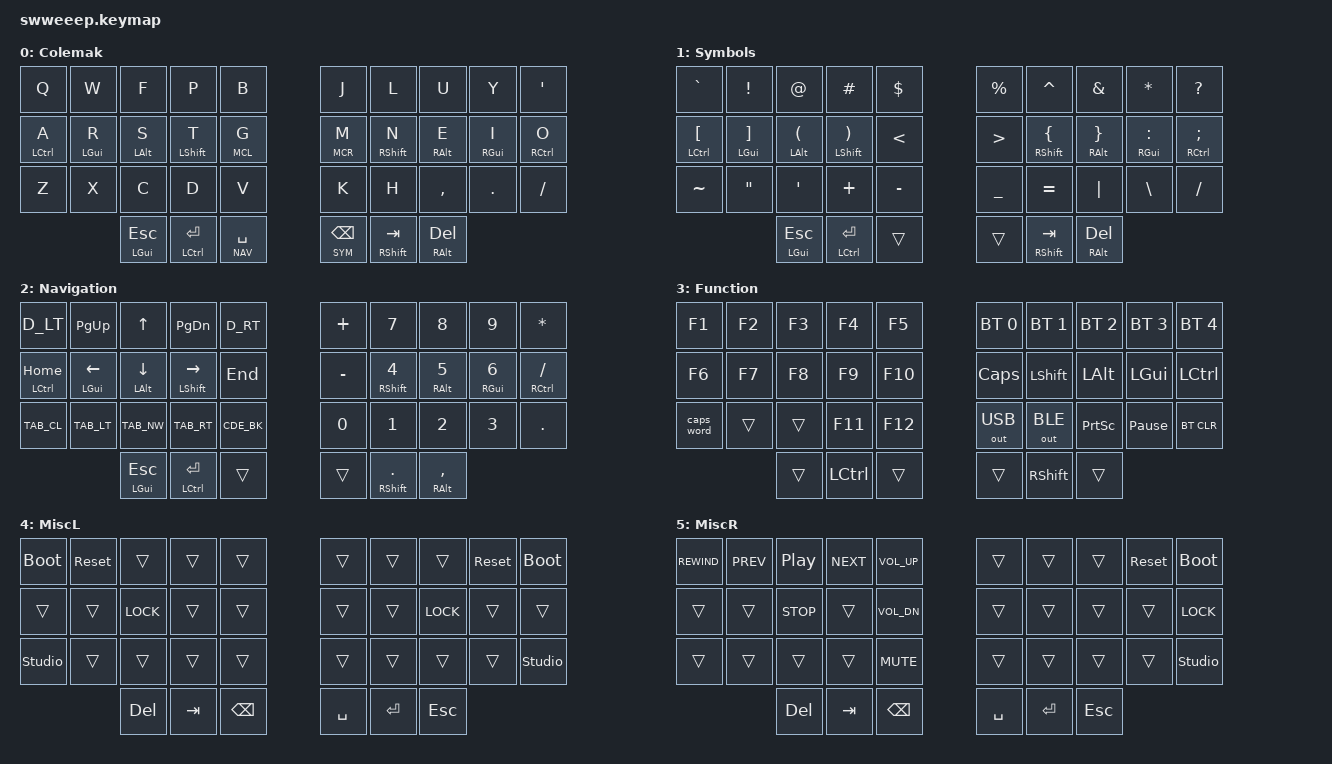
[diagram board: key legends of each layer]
#include <behaviors.dtsi>
#include <dt-bindings/zmk/keys.h>
#include <dt-bindings/zmk/bt.h>
#include <dt-bindings/zmk/outputs.h>

// Layer aliases
#define CMK  0
#define SYM  1
#define NAV  2
#define FUN  3
#define MCL  4
#define MCR  5

// Desktop keycodes
#define D_LT   LC(LA(LEFT))
#define D_RT   LC(LA(RIGHT))

// Browser keycodes
#define TAB_NW LC(T)
#define TAB_RT LC(TAB)
#define TAB_LT LC(LS(TAB))
#define TAB_CL LC(W)

// VS Code keycodes
#define CDE_BK LC(LA(MINUS))
#define CDE_FD LC(LS(MINUS))

// Key position groups
#define KEYS_L 0 1 2 3 4 10 11 12 13 14 20 21 22 23 24
#define KEYS_R 5 6 7 8 9 15 16 17 18 19 25 26 27 28 29
#define THUMBS 30 31 32 33 34 35 

// #include "combos.dtsi"

&caps_word {
    continue-list = <UNDERSCORE MINUS BSPC DEL N1 N2 N3 N4 N5 N6 N7 N8 N9 N0>;
};


/ {
    behaviors {    
          hml: homerow_mods_left {
               compatible = "zmk,behavior-hold-tap";
               display-name = "HM Left";
               #binding-cells = <2>;
               flavor = "balanced";
               require-prior-idle-ms = <150>;
               tapping-term-ms = <200>;
               quick-tap-ms = <150>;
               bindings = <&kp>, <&kp>;
               hold-trigger-key-positions = <KEYS_R THUMBS>;
               hold-trigger-on-release;
          };
          hmr: homerow_mods_right {
               compatible = "zmk,behavior-hold-tap";
               display-name = "HM Right";
               #binding-cells = <2>;
               flavor = "balanced";
               require-prior-idle-ms = <150>;
               tapping-term-ms = <200>;
               quick-tap-ms = <150>;
               bindings = <&kp>, <&kp>;
               hold-trigger-key-positions = <KEYS_L THUMBS>;
               hold-trigger-on-release;
          };
          hmt: homerow_mods_toggle {
               compatible = "zmk,behavior-hold-tap";
               display-name = "HM Toggle";
               #binding-cells = <2>;
               flavor = "balanced";
               require-prior-idle-ms = <150>;
               tapping-term-ms = <200>;
               quick-tap-ms = <150>;
               bindings = <&mo>, <&kp>;
               hold-trigger-key-positions = <KEYS_L KEYS_R THUMBS>;
               hold-trigger-on-release;
          };
          ltr: layer_toggle_right {
               compatible = "zmk,behavior-hold-tap";
               display-name = "LT Right";
               #binding-cells = <2>;
               flavor = "hold-preferred";
               tapping-term-ms = <200>;
               bindings = <&mo>, <&kp>;
          };
          ltl: layer_toggle_left {
               compatible = "zmk,behavior-hold-tap";
               display-name = "LT Left";
               #binding-cells = <2>;
               flavor = "hold-preferred";
               tapping-term-ms = <200>;
               bindings = <&mo>, <&kp>;
          };
    };

    cond_layers {
        compatible = "zmk,conditional-layers";
        // Define FUN layer as tri-state
        func_tristate {
            if-layers = <NAV SYM>;
            then-layer = <FUN>;
        };
    };

    keymap {
       compatible = "zmk,keymap";
       Colemak_layer {
          display-name = "Colemak";
          bindings = <

// ╭─────────────┬─────────────┬─────────────┬─────────────┬─────────────╮   ╭─────────────┬─────────────┬─────────────┬─────────────┬─────────────╮
     &kp Q         &kp W         &kp F         &kp P         &kp B             &kp J         &kp L         &kp U         &kp Y         &kp SQT
// ├─────────────┼─────────────┼─────────────┼─────────────┼─────────────┤   ├─────────────┼─────────────┼─────────────┼─────────────┼─────────────┤
     &hml LCTRL A  &hml LGUI R   &hml LALT S   &hml LSHFT T  &hmt MCL G        &hmt MCR M    &hmr RSHFT N  &hmr RALT E   &hmr RGUI I   &hmr RCTRL O
// ├─────────────┼─────────────┼─────────────┼─────────────┼─────────────┤   ├─────────────┼─────────────┼─────────────┼─────────────┼─────────────┤
     &kp Z         &kp X         &kp C         &kp D         &kp V             &kp K         &kp H         &kp COMMA     &kp DOT       &kp SLASH
// ╰─────────────┴─────────────┴─────────────┼─────────────┼─────────────┤   ├─────────────┼─────────────┼─────────────┴─────────────┴─────────────╯
                                 &mt LGUI ESC  &mt LCTRL RET &ltr NAV SPACE    &ltl SYM BSPC &mt RSHFT TAB &mt RALT DEL
//                             ╰─────────────┴─────────────┴─────────────╯   ╰─────────────┴─────────────┴─────────────╯
        >;

     };
     Symbols_layer {
          display-name = "Symbols";
          bindings = <

// ╭─────────────┬─────────────┬─────────────┬─────────────┬─────────────╮   ╭─────────────┬─────────────┬─────────────┬─────────────┬─────────────╮
     &kp GRAVE     &kp EXCL      &kp AT        &kp HASH      &kp DLLR          &kp PRCNT     &kp CARET     &kp AMPS      &kp ASTRK     &kp QMARK
// ├─────────────┼─────────────┼─────────────┼─────────────┼─────────────┤   ├─────────────┼─────────────┼─────────────┼─────────────┼─────────────┤
     &hml LCTRL LBKT  &hml LGUI RBKT &hml LALT LPAR &hml LSHIFT RPAR &kp LT    &kp GT   &hmr RSHFT LBRC &hmr RALT RBRC &hmr RGUI COLON &hmr RCTRL SEMI
// ├─────────────┼─────────────┼─────────────┼─────────────┼─────────────┤   ├─────────────┼─────────────┼─────────────┼─────────────┼─────────────┤
     &kp TILDE     &kp DQT       &kp SQT       &kp PLUS      &kp MINUS         &kp UNDER      &kp EQUAL     &kp PIPE     &kp BSLH       &kp SLASH
// ╰─────────────┴─────────────┴─────────────┼─────────────┼─────────────┤   ├─────────────┼─────────────┼─────────────┴─────────────┴─────────────╯
                                 &mt LGUI ESC  &mt LCTRL RET &trans            &trans        &mt RSHFT TAB &mt RALT DEL
//                             ╰─────────────┴─────────────┴─────────────╯   ╰─────────────┴─────────────┴─────────────╯
        >;

     };
     Navigation_layer {
          display-name = "Navigation";
          bindings = <

// ╭─────────────┬─────────────┬─────────────┬─────────────┬─────────────╮   ╭─────────────┬─────────────┬─────────────┬─────────────┬─────────────╮
     &kp D_LT      &kp PG_UP     &kp UP        &kp PG_DN     &kp D_RT           &kp PLUS      &kp N7        &kp N8       &kp N9         &kp STAR
// ├─────────────┼─────────────┼─────────────┼─────────────┼─────────────┤   ├─────────────┼─────────────┼─────────────┼─────────────┼─────────────┤
     &hml LCTRL HOME &hml LGUI LEFT &hml LALT DOWN &hml LSHFT RIGHT &kp END     &kp MINUS     &hmr RSHFT N4 &hmr RALT N5 &hmr RGUI N6   &hmr RCTRL SLASH
// ├─────────────┼─────────────┼─────────────┼─────────────┼─────────────┤   ├─────────────┼─────────────┼─────────────┼─────────────┼─────────────┤
     &kp TAB_CL    &kp TAB_LT    &kp TAB_NW    &kp TAB_RT    &kp CDE_BK         &kp N0        &kp N1        &kp N2        &kp N3         &kp DOT
// ╰─────────────┴─────────────┴─────────────┼─────────────┼─────────────┤   ├─────────────┼─────────────┼─────────────┴─────────────┴─────────────╯
                                 &mt LGUI ESC  &mt LCTRL RET &trans             &trans        &mt RSHFT DOT &mt RALT COMMA
//                             ╰─────────────┴─────────────┴─────────────╯   ╰─────────────┴─────────────┴─────────────╯
        >;


     };
     Function_layer {
          display-name = "Function";
          bindings = <

// ╭─────────────┬─────────────┬─────────────┬─────────────┬─────────────╮   ╭─────────────┬─────────────┬─────────────┬─────────────┬─────────────╮
     &kp F1        &kp F2        &kp F3        &kp F4        &kp F5            &bt BT_SEL 0  &bt BT_SEL 1  &bt BT_SEL 2  &bt BT_SEL 3  &bt BT_SEL 4
// ├─────────────┼─────────────┼─────────────┼─────────────┼─────────────┤   ├─────────────┼─────────────┼─────────────┼─────────────┼─────────────┤
     &kp F6        &kp F7        &kp F8        &kp F9        &kp F10           &kp CAPS      &kp LSHIFT    &kp LALT      &kp LGUI      &kp LCTRL
// ├─────────────┼─────────────┼─────────────┼─────────────┼─────────────┤   ├─────────────┼─────────────┼─────────────┼─────────────┼─────────────┤
     &caps_word    &trans        &trans        &kp F11       &kp F12           &out OUT_USB  &out OUT_BLE  &kp PSCRN    &kp PAUSE_BREAK &bt BT_CLR
// ╰─────────────┴─────────────┴─────────────┼─────────────┼─────────────┤   ├─────────────┼─────────────┼─────────────┴─────────────┴─────────────╯
                                  &trans        &kp LCTRL      &trans            &trans        &kp RSHIFT     &trans
//                             ╰─────────────┴─────────────┴─────────────╯   ╰─────────────┴─────────────┴─────────────╯
        >;

     };
     MiscL_layer {
          display-name = "MiscL";
          bindings = <

// ╭─────────────┬─────────────┬─────────────┬─────────────┬─────────────╮   ╭─────────────┬─────────────┬─────────────┬─────────────┬─────────────╮
       &bootloader   &sys_reset    &trans        &trans        &trans            &trans        &trans        &trans        &sys_reset    &bootloader
// ├─────────────┼─────────────┼─────────────┼─────────────┼─────────────┤   ├─────────────┼─────────────┼─────────────┼─────────────┼─────────────┤
       &trans        &trans        &kp K_LOCK    &trans        &trans            &trans        &trans        &kp K_LOCK    &trans        &trans    
// ├─────────────┼─────────────┼─────────────┼─────────────┼─────────────┤   ├─────────────┼─────────────┼─────────────┼─────────────┼─────────────┤
       &studio_unlock&trans        &trans        &trans        &trans            &trans        &trans        &trans        &trans        &studio_unlock
// ╰─────────────┴─────────────┴─────────────┼─────────────┼─────────────┤   ├─────────────┼─────────────┼─────────────┴─────────────┴─────────────╯
                                   &kp DEL       &kp TAB       &kp BSPC           &kp SPACE     &kp RET     &kp ESC
//                             ╰─────────────┴─────────────┴─────────────╯   ╰─────────────┴─────────────┴─────────────╯
        >;

     };
     MiscR_layer {
          display-name = "MiscR";
          bindings = <

// ╭─────────────┬─────────────┬─────────────┬─────────────┬─────────────╮   ╭─────────────┬─────────────┬─────────────┬─────────────┬─────────────╮
     &kp C_REWIND  &kp C_PREV    &kp C_PP      &kp C_NEXT    &kp C_VOL_UP        &trans        &trans        &trans        &sys_reset    &bootloader
// ├─────────────┼─────────────┼─────────────┼─────────────┼─────────────┤   ├─────────────┼─────────────┼─────────────┼─────────────┼─────────────┤
       &trans        &trans       &kp C_STOP     &trans      &kp C_VOL_DN        &trans        &trans        &trans        &trans        &kp K_LOCK
// ├─────────────┼─────────────┼─────────────┼─────────────┼─────────────┤   ├─────────────┼─────────────┼─────────────┼─────────────┼─────────────┤
       &trans        &trans        &trans        &trans      &kp C_MUTE          &trans        &trans        &trans        &trans        &studio_unlock
// ╰─────────────┴─────────────┴─────────────┼─────────────┼─────────────┤   ├─────────────┼─────────────┼─────────────┴─────────────┴─────────────╯
                                   &kp DEL       &kp TAB       &kp BSPC           &kp SPACE     &kp RET     &kp ESC
//                             ╰─────────────┴─────────────┴─────────────╯   ╰─────────────┴─────────────┼─────────────╯
        >;
    };
  };
};
